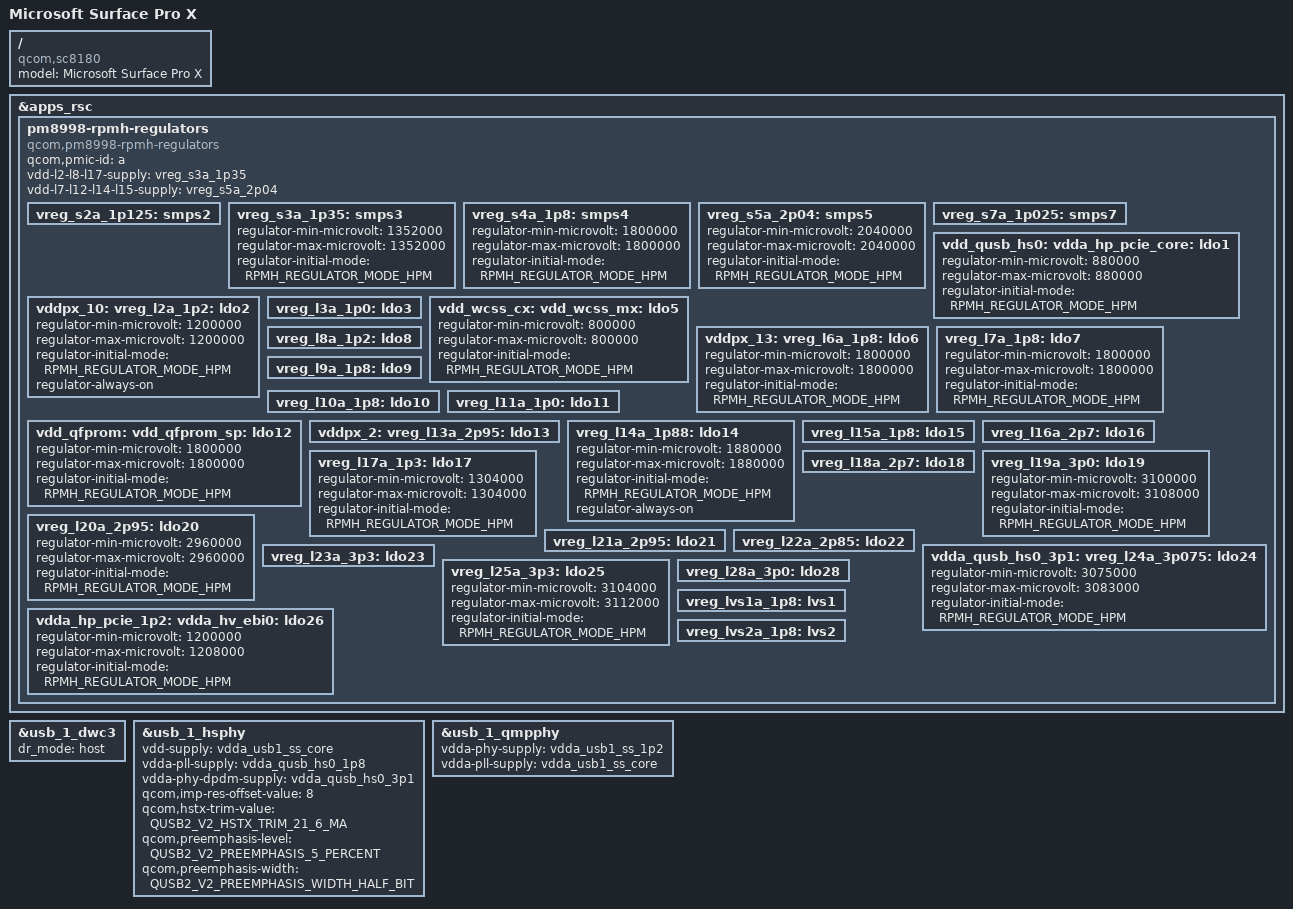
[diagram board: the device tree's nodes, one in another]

// SPDX-License-Identifier: BSD-3-Clause

/dts-v1/;

#include <dt-bindings/regulator/qcom,rpmh-regulator.h>
#include "sc8180.dtsi"

/ {
	model = "Microsoft Surface Pro X";
	compatible = "qcom,sc8180";

};

&apps_rsc {
	pm8998-rpmh-regulators {
		compatible = "qcom,pm8998-rpmh-regulators";
		qcom,pmic-id = "a";

		vdd-l2-l8-l17-supply = <&vreg_s3a_1p35>;
		vdd-l7-l12-l14-l15-supply = <&vreg_s5a_2p04>;

		vreg_s2a_1p125: smps2 {
		};

		vreg_s3a_1p35: smps3 {
			regulator-min-microvolt = <1352000>;
			regulator-max-microvolt = <1352000>;
			regulator-initial-mode = <RPMH_REGULATOR_MODE_HPM>;
		};

		vreg_s4a_1p8: smps4 {
			regulator-min-microvolt = <1800000>;
			regulator-max-microvolt = <1800000>;
			regulator-initial-mode = <RPMH_REGULATOR_MODE_HPM>;
		};

		vreg_s5a_2p04: smps5 {
			regulator-min-microvolt = <2040000>;
			regulator-max-microvolt = <2040000>;
			regulator-initial-mode = <RPMH_REGULATOR_MODE_HPM>;
		};

		vreg_s7a_1p025: smps7 {
		};

		vdd_qusb_hs0:
		vdda_hp_pcie_core:
		vdda_mipi_csi0_0p9:
		vdda_mipi_csi1_0p9:
		vdda_mipi_csi2_0p9:
		vdda_mipi_dsi0_pll:
		vdda_mipi_dsi1_pll:
		vdda_qlink_lv:
		vdda_qlink_lv_ck:
		vdda_qrefs_0p875:
		vdda_pcie_core:
		vdda_pll_cc_ebi01:
		vdda_pll_cc_ebi23:
		vdda_sp_sensor:
		vdda_ufs1_core:
		vdda_ufs2_core:
		vdda_usb1_ss_core:
		vdda_usb2_ss_core:
		vreg_l1a_0p875: ldo1 {
			regulator-min-microvolt = <880000>;
			regulator-max-microvolt = <880000>;
			regulator-initial-mode = <RPMH_REGULATOR_MODE_HPM>;
		};

		vddpx_10:
		vreg_l2a_1p2: ldo2 {
			regulator-min-microvolt = <1200000>;
			regulator-max-microvolt = <1200000>;
			regulator-initial-mode = <RPMH_REGULATOR_MODE_HPM>;
			regulator-always-on;
		};

		vreg_l3a_1p0: ldo3 {
		};

		vdd_wcss_cx:
		vdd_wcss_mx:
		vdda_wcss_pll:
		vreg_l5a_0p8: ldo5 {
			regulator-min-microvolt = <800000>;
			regulator-max-microvolt = <800000>;
			regulator-initial-mode = <RPMH_REGULATOR_MODE_HPM>;
		};

		vddpx_13:
		vreg_l6a_1p8: ldo6 {
			regulator-min-microvolt = <1800000>;
			regulator-max-microvolt = <1800000>;
			regulator-initial-mode = <RPMH_REGULATOR_MODE_HPM>;
		};

		vreg_l7a_1p8: ldo7 {
			regulator-min-microvolt = <1800000>;
			regulator-max-microvolt = <1800000>;
			regulator-initial-mode = <RPMH_REGULATOR_MODE_HPM>;
		};

		vreg_l8a_1p2: ldo8 {
		};

		vreg_l9a_1p8: ldo9 {
		};

		vreg_l10a_1p8: ldo10 {
		};

		vreg_l11a_1p0: ldo11 {
		};

		vdd_qfprom:
		vdd_qfprom_sp:
		vdda_apc1_cs_1p8:
		vdda_gfx_cs_1p8:
		vdda_qrefs_1p8:
		vdda_qusb_hs0_1p8:
		vddpx_11:
		vreg_l12a_1p8: ldo12 {
			regulator-min-microvolt = <1800000>;
			regulator-max-microvolt = <1800000>;
			regulator-initial-mode = <RPMH_REGULATOR_MODE_HPM>;
		};

		vddpx_2:
		vreg_l13a_2p95: ldo13 {
		};

		vreg_l14a_1p88: ldo14 {
			regulator-min-microvolt = <1880000>;
			regulator-max-microvolt = <1880000>;
			regulator-initial-mode = <RPMH_REGULATOR_MODE_HPM>;
			regulator-always-on;
		};

		vreg_l15a_1p8: ldo15 {
		};

		vreg_l16a_2p7: ldo16 {
		};

		vreg_l17a_1p3: ldo17 {
			regulator-min-microvolt = <1304000>;
			regulator-max-microvolt = <1304000>;
			regulator-initial-mode = <RPMH_REGULATOR_MODE_HPM>;
		};

		vreg_l18a_2p7: ldo18 {
		};

		vreg_l19a_3p0: ldo19 {
			regulator-min-microvolt = <3100000>;
			regulator-max-microvolt = <3108000>;
			regulator-initial-mode = <RPMH_REGULATOR_MODE_HPM>;
		};

		vreg_l20a_2p95: ldo20 {
			regulator-min-microvolt = <2960000>;
			regulator-max-microvolt = <2960000>;
			regulator-initial-mode = <RPMH_REGULATOR_MODE_HPM>;
		};

		vreg_l21a_2p95: ldo21 {
		};

		vreg_l22a_2p85: ldo22 {
		};

		vreg_l23a_3p3: ldo23 {
		};

		vdda_qusb_hs0_3p1:
		vreg_l24a_3p075: ldo24 {
			regulator-min-microvolt = <3075000>;
			regulator-max-microvolt = <3083000>;
			regulator-initial-mode = <RPMH_REGULATOR_MODE_HPM>;
		};

		vreg_l25a_3p3: ldo25 {
			regulator-min-microvolt = <3104000>;
			regulator-max-microvolt = <3112000>;
			regulator-initial-mode = <RPMH_REGULATOR_MODE_HPM>;
		};

		vdda_hp_pcie_1p2:
		vdda_hv_ebi0:
		vdda_hv_ebi1:
		vdda_hv_ebi2:
		vdda_hv_ebi3:
		vdda_mipi_csi_1p25:
		vdda_mipi_dsi0_1p2:
		vdda_mipi_dsi1_1p2:
		vdda_pcie_1p2:
		vdda_ufs1_1p2:
		vdda_ufs2_1p2:
		vdda_usb1_ss_1p2:
		vdda_usb2_ss_1p2:
		vreg_l26a_1p2: ldo26 {
			regulator-min-microvolt = <1200000>;
			regulator-max-microvolt = <1208000>;
			regulator-initial-mode = <RPMH_REGULATOR_MODE_HPM>;
		};

		vreg_l28a_3p0: ldo28 {
		};

		vreg_lvs1a_1p8: lvs1 {
		};

		vreg_lvs2a_1p8: lvs2 {
		};
	};
};

//&usb_1 {
//	status = "okay";
//};

&usb_1_dwc3 {
	dr_mode = "host";
};

&usb_1_hsphy {
	status = "okay";

	vdd-supply = <&vdda_usb1_ss_core>;
	vdda-pll-supply = <&vdda_qusb_hs0_1p8>;
	vdda-phy-dpdm-supply = <&vdda_qusb_hs0_3p1>;

	qcom,imp-res-offset-value = <8>;
	qcom,hstx-trim-value = <QUSB2_V2_HSTX_TRIM_21_6_MA>;
	qcom,preemphasis-level = <QUSB2_V2_PREEMPHASIS_5_PERCENT>;
	qcom,preemphasis-width = <QUSB2_V2_PREEMPHASIS_WIDTH_HALF_BIT>;
};

&usb_1_qmpphy {
	status = "okay";

	vdda-phy-supply = <&vdda_usb1_ss_1p2>;
	vdda-pll-supply = <&vdda_usb1_ss_core>;
};
